# S1C31D50 register map
Vendor: Epson; Series: S1C31D50; File version: 1.00
CPU: CM0PLUS r0p1, little endian, MPU, no FPU, VTOR, 2 interrupt priority bits
Registers are 16-bit, read-write, reset 0x0 unless marked. A register's access mark holds for its fields unless they carry their own. Offsets are from the block's base; [hi:lo] are bit positions.

## CACHE — Cache controller
Base 0x00200080
0x00 CTL reset 0x2 — Cache Control Register
  [0] CACHEEN — Cache enable
    0=DISABLE (Disable (Also refer to VALID_BIT_RST_DIS)); 1=ENABLE

## DMAC — PrimeCell uDMA Controller
Base 0x00201000
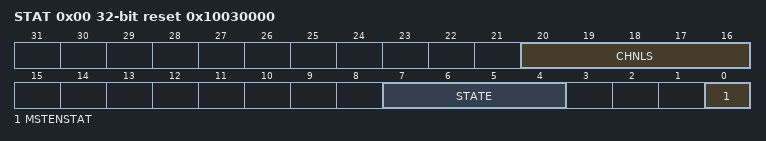
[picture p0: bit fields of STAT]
0x00 STAT 32-bit ro reset 0x10030000 — Returns the DMAC status
  [20:16] CHNLS — Number of available DMAC channels minus one
  [7:4] STATE — These bits indicates the DMA transfer status
  [0] MSTENSTAT — This bit indicates the DMA controller status
0x04 CFG 32-bit — DMA configuration
  [0] MSTEN wo — This bit enables the DMA controller.
0x08 CPTR 32-bit — Pointer to the base address of the primary data structure
  [31:0] CPTR — DMAC Control Data Base Pointer Reg.
0x0C ACPTR 32-bit ro — Pointer to the base address of the alternative data structure
  [31:0] ACPTR — These bits show the alternate data structure base address
0x14 SWREQ 32-bit wo — The write-only register enables you to generate a software DMA request
  [3:0] SWREQ — These bits issue a software DMA transfer request to each channel
0x20 RMSET 32-bit — Setting this bit to 1 causes the DMA channel to no longer respond to data requests from peripherals. The channel will always respond to software transfer requests
  [3:0] RMSET
0x24 RMCLR 32-bit wo — Firmware can write a 1 to the register to clear the mask for a channel
  [3:0] RMCLR
0x28 ENSET 32-bit — These bits enable each DMAC channel. Returns the enable status of the channels
  [3:0] ENSET
0x2C ENCLR 32-bit wo — Set the appropriate bit to disable the corresponding DMA channel
  [3:0] EMCLR
0x30 PASET 32-bit — These bits enable the alternate data structures. Returns status of alternate structures.
  [3:0] PASET
0x34 PACLR 32-bit wo — These bits disable the alternate data structures
  [3:0] PACLR
0x38 PRSET 32-bit — These bits increase the priority of each channel
  [3:0] PRSET
0x3C PRCLR 32-bit wo — These bits decrease the priority of each channel
  [3:0] PRCLR
0x4C ERRIF 32-bit — DMAC Error Interrupt Flag Register
  [0] ERRIF — Returns the status of DMAC error. Cleared by writing 1
0x1000 ENDIF 32-bit — DMAC Transfer Completion Interrupt cause occurrence status Flag Register
  [3:0] ENDIF — These bits indicate the DMA transfer completion interrupt cause occurrence status of each DMAC channel. Cleared by writing 1.
0x1008 ENDIESET 32-bit — DMAC Transfer Completion Interrupt Enable Set Register
  [3:0] ENDIESET — Enables DMA transfer completion interrupts to be generated for each DMAC channel.
0x100C ENDIECLR 32-bit wo — DMAC Transfer Completion Interrupt Enable Clear Register
  [3:0] ENDIECLR — Clears/disables DMA transfer completion interrupts to be generated for each DMAC channel.
0x1010 ERRIESET 32-bit — DMAC Error Interrupt Enable Set Register
  [0] ERRIESET — Sets DMA error interrupt enable.
    0=DISABLE/IGNORE; 1=ENABLE/SET
0x1014 ERRIECLR 32-bit wo — DMAC Error Interrupt Enable Clear Register
  [0] ERRIECLR — Clears DMA error interrupt enable.
    0=IGNORE; 1=CLEAR

## FLASHC — Flash controller
Base 0x002001B0
0x00 WAIT reset 0x1 — Flash Read Cycle Register
  [1:0] RDWAIT — RdCycle Number of cycles (can be write protected)

## PWGA — Operation mode and voltage control
Base 0x00200020
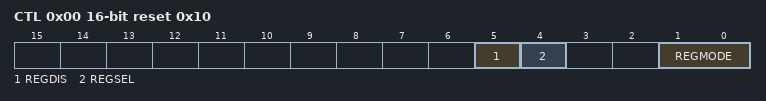
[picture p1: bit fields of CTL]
0x00 CTL reset 0x10 — Control Register
  [5] REGDIS — Regulator discharge enable (can be write protected)
    0=NORMAL (Normal operation); 1=DISCHARGE (Regulator discharge)
  [4] REGSEL — Regulator voltage select (can be write protected)
    0=1_2V; 1=1_8V
  [1:0] REGMODE — Regulator operation mode select (can be write protected)
    0=AUTO (Automatic mode); 2=NORM (Normal mode); 3=ECON (Economy mode)
